# RN821X_RN721X_SOC_B register map
File version: v1.0.6
CPU: CM0 r0p0, little endian, no MPU, no FPU, 3 interrupt priority bits
Registers are 32-bit, read-write, reset 0x0 unless marked. A register's access mark holds for its fields unless they carry their own. Offsets are from the block's base; [hi:lo] are bit positions; {n}, {i} and the like mark numbered series.

## SPI0 — synchronous peripheral interface
Base 0x40020000
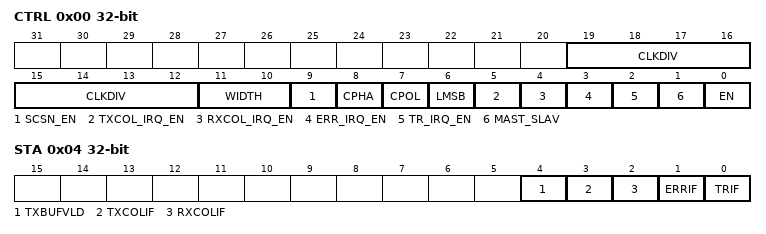
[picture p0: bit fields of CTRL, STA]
0x00 CTRL — SPI control register
  [19:12] CLKDIV — clock divisor for SCK.frequency of SCK is (frequency of system clock)/(2*(CLKDIV+1))
  [11:10] WIDTH — data width selection
    0=8BIT (select data width as 8 bit); 1=16BIT (select data width as 16 bit); 2=32BIT (select data width as 32 bit)
  [9] SCSN_EN — SCSN error detection enable.applicable in master mode
  [8] CPHA — clock phase selection
    0=SAMP (leading edge sampling data, trailing edge build data); 1=BUILD (leading edge build data, trailing edge sampling data)
  [7] CPOL — clock polarity selection
    0=EL (select low level for 'SCK' empty status); 1=EH (select high level for 'SCK' empty status)
  [6] LMSB — LSB or MSB selection
    0=MSB (MSB transmitted first); 1=LSB (LSB transmitted first)
  [5] TXCOL_IRQ_EN — transmit data collision interrupt enable
  [4] RXCOL_IRQ_EN — receive data collision interrupt enable
  [3] ERR_IRQ_EN — SCSN error interrupt enable
  [2] TR_IRQ_EN — transmit interrupt enable
  [1] MAST_SLAV — master slave selection
    1=M (select as master device); 0=S (select as slave device)
  [0] EN — module enable
0x04 STA — SPI status register
  [4] TXBUFVLD — transmit buffer not empty flag
  [3] TXCOLIF write-1-clears — transmit data overflow interrupt flag
  [2] RXCOLIF write-1-clears — receive data overflow interrupt flag
  [1] ERRIF write-1-clears — SCSN error interrupt flag
  [0] TRIF write-1-clears — transmit interrupt flag
0x08 TX — SPI transmit data register
  [31:0] TX — transmit data bits
0x0C RX ro — SPI receive data register
  [31:0] RX — receive data bits

## UART0 — UART tranceiver
Base 0x40000000
Same registers: UART1 0x40004000, UART2 0x40008000, UART3 0x4000C000, UART4 0x40018000, UART5 0x4001C000
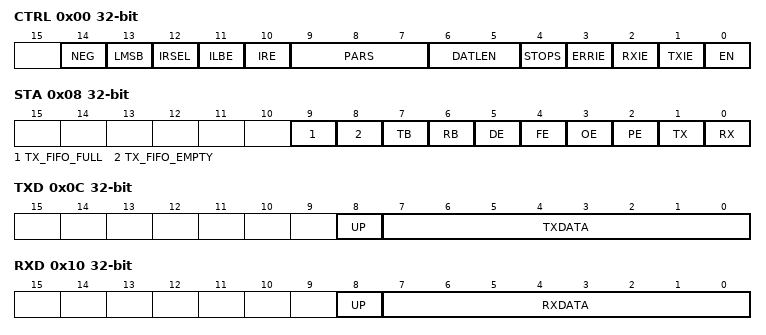
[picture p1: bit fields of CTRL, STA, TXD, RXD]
0x00 CTRL — UART control register
  [14] NEG — UART transfer polarity selection bit
    0=P (positive polarity (default driving voltage is high)); 1=N (negative polarity (default driving voltage is low))
  [13] LMSB — LSB/MSB transfer mode selection
    0=L (LSB first transfer mode); 1=M (MSB first transfer mode)
  [12] IRSEL — infra-red modulation polarity selection bit
    0=P (positive polarity. default driving voltage is high); 1=N (negative polarity. default driving voltage is low)
  [11] ILBE — inner loopback enable bit
  [10] IRE — infra-red modulation enable bit
  [9:7] PARS — parity type selection bits
    0=NUL (parity type select no parity); 1=ODD (parity type select odd parity); 2=EVEN (parity type select even parity); 3=parity type select stick_zero parity; 4=parity type select stick one parity; 5=USER (parity type select user_defined parity)
  [6:5] DATLEN — data length of frame format Configuration bits
    {v}=select {v+5} bits of data field (v=0..3)
  [4] STOPS — stop bits width selection bit
    1=2BIT (stop bit_width select as 2 bit); 0=1BIT (stop bit_width select as 1 bit)
  [3] ERRIE — error interrupt enable bit
  [2] RXIE — receive interrupt enable bit
  [1] TXIE — transmit interrupt enable bit
  [0] EN — UART module enable bit
0x04 BAUD — UART baud rate configuration register
  [11:0] CLKDIV — baud rate configuration bits
0x08 STA — UART status register
  [9] TX_FIFO_FULL — transmit fifo full flag
  [8] TX_FIFO_EMPTY — transmit fifo empty flag
  [7] TB — transmit busy flag
  [6] RB — receive busy flag
  [5] DE write-1-clears — data error flag
  [4] FE write-1-clears — frame error flag
  [3] OE write-1-clears — overflow error flag
  [2] PE write-1-clears — parity error flag
  [1] TX write-1-clears — transmit finish flag
  [0] RX write-1-clears — receive finish flag
0x0C TXD — UART transmit data register
  [8] UP — User-defined parity bit(valid when user-defined parity selected)
  [7:0] TXDATA — Transmit data value
0x10 RXD — UART receive data register
  [8] UP ro — user-defined parity bit(valid when user-defined parity selected)
  [7:0] RXDATA ro — Received data value bits
0x14 FDIV — baud rate fractional part
  [13:0] FDIV — baud rate fractional divisor configuration bits

## WDT — watchdog timer
Base 0x40030000
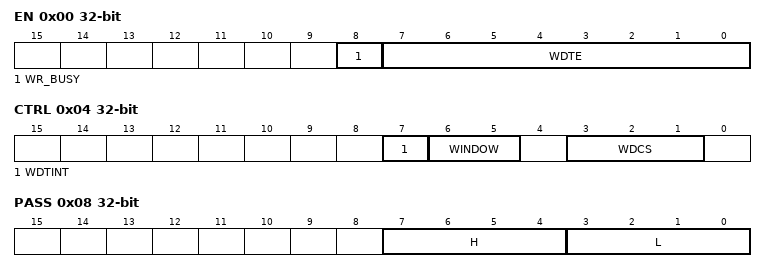
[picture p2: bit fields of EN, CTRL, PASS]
0x00 EN — Watchdog enable register
  [8] WR_BUSY ro — WDT write busy flag
  [7:0] WDTE — WDT enable bits
    187=RESTART (clear WDT counter and restart WDT(write value)); 85=DIS_DFLT (WDTE default value)
0x04 CTRL — WDT control register
  [7] WDTINT — WDT Timer Interval Interrupt
  [6:5] WINDOW — WDT Window Open Period
  [3:1] WDCS — WDT overflow time config
0x08 PASS — WDT password register
  [7:4] H ro — WDT high part password
  [3:0] L — WDT low part password
0x14 HALT — WDT HALT control register
  [15:0] EN — HALT_EN config bits
0x18 STBY — WDT STBY control register
  [15:0] EN — STBY_EN config bits
